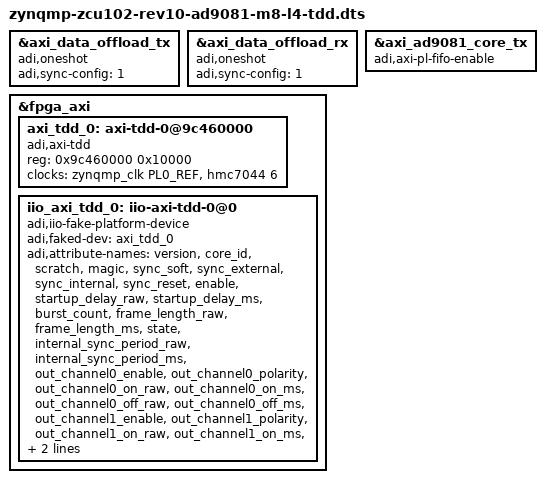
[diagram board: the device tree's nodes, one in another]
// SPDX-License-Identifier: GPL-2.0
/*
 * Analog Devices AD9081-FMC-EBZ
 * https://wiki.analog.com/resources/eval/user-guides/quadmxfe/quick-start
 * https://wiki.analog.com/resources/tools-software/linux-drivers/iio-mxfe/ad9081
 *
 * hdl_project: <ad9081_fmca_ebz/zcu102>
 * board_revision: <>
 *
 * Copyright (C) 2021 Analog Devices Inc.
 */

#include "zynqmp-zcu102-rev10-ad9081-m8-l4-do.dts"

&axi_data_offload_tx {
	adi,oneshot;
	adi,sync-config = <1>;
};

&axi_data_offload_rx {
	adi,oneshot;
	adi,sync-config = <1>;
};

&fpga_axi {
	axi_tdd_0: axi-tdd-0@9c460000 {
		compatible = "adi,axi-tdd";
		reg = <0x9c460000 0x10000>;
		clocks = <&zynqmp_clk PL0_REF>, <&hmc7044 6>;
		clock-names = "s_axi_aclk", "intf_clk";
	};

	iio_axi_tdd_0: iio-axi-tdd-0@0 {
		compatible = "adi,iio-fake-platform-device";
		adi,faked-dev = <&axi_tdd_0>;
		adi,attribute-names =
			"version", "core_id", "scratch", "magic",
			"sync_soft", "sync_external", "sync_internal", "sync_reset",
			"enable", "startup_delay_raw", "startup_delay_ms",
			"burst_count", "frame_length_raw", "frame_length_ms",
			"state", "internal_sync_period_raw", "internal_sync_period_ms",
			"out_channel0_enable", "out_channel0_polarity",
			"out_channel0_on_raw", "out_channel0_on_ms",
			"out_channel0_off_raw", "out_channel0_off_ms",
			"out_channel1_enable", "out_channel1_polarity",
			"out_channel1_on_raw", "out_channel1_on_ms",
			"out_channel1_off_raw", "out_channel1_off_ms";
		label = "axi-core-tdd";
	};
};

&axi_ad9081_core_tx {
	adi,axi-pl-fifo-enable;
};

